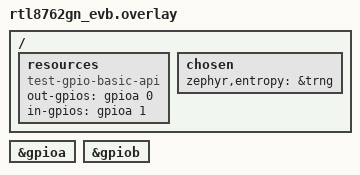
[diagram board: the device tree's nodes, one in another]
/*
 * Copyright(c) 2025, Realtek Semiconductor Corporation.
 *
 * SPDX-License-Identifier: Apache-2.0
 */

#include <zephyr/dt-bindings/gpio/realtek-bee-gpio.h>

&gpioa {
	status = "okay";
};

&gpiob {
	status = "okay";
};

/ {
	resources {
		compatible = "test-gpio-basic-api";
		out-gpios = <&gpioa 0 GPIO_ACTIVE_HIGH>;
		in-gpios = <&gpioa 1 (GPIO_ACTIVE_HIGH | BEE_GPIO_INPUT_DEBOUNCE_MS(8))>;
	};

	chosen {
		zephyr,entropy = &trng;
	};
};
